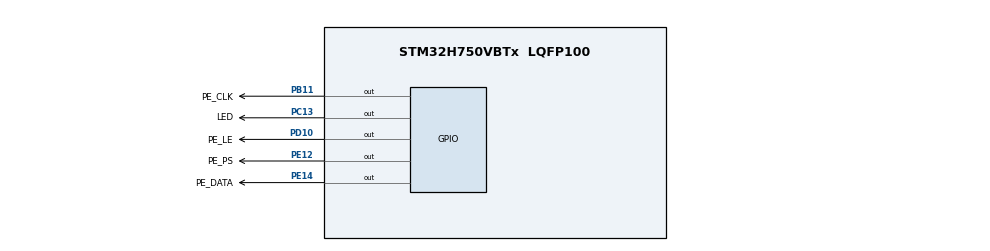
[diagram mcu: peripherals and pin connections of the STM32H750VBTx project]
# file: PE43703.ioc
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CORTEX_M7.CPU_DCache=Disabled
CORTEX_M7.CPU_ICache=Disabled
CORTEX_M7.default_mode_Activation=1
Mcu.Family=STM32H7
Mcu.Name=STM32H750VBTx
Mcu.Package=LQFP100
NVIC.PriorityGroup=NVIC_PRIORITYGROUP_4
PA13\ (JTMS/SWDIO).Mode=Serial_Wire
PA13\ (JTMS/SWDIO).Signal=DEBUG_JTMS-SWDIO
PA14\ (JTCK/SWCLK).Mode=Serial_Wire
PA14\ (JTCK/SWCLK).Signal=DEBUG_JTCK-SWCLK
PB11.GPIO_Label=PE_CLK
PB11.GPIO_Speed=GPIO_SPEED_FREQ_VERY_HIGH
PB11.Signal=GPIO_Output
PC13.GPIO_Label=LED
PC13.Signal=GPIO_Output
PD10.GPIO_Label=PE_LE
PD10.GPIO_Speed=GPIO_SPEED_FREQ_VERY_HIGH
PD10.Signal=GPIO_Output
PE12.GPIO_Label=PE_PS
PE12.GPIO_Speed=GPIO_SPEED_FREQ_VERY_HIGH
PE12.PinState=GPIO_PIN_SET
PE12.Signal=GPIO_Output
PE14.GPIO_Label=PE_DATA
PE14.GPIO_Speed=GPIO_SPEED_FREQ_VERY_HIGH
PE14.Signal=GPIO_Output
PH0-OSC_IN\ (PH0).Mode=HSE-External-Clock-Source
PH0-OSC_IN\ (PH0).Signal=RCC_OSC_IN
ProjectManager.HeapSize=0x200
ProjectManager.StackSize=0x400
ProjectManager.TargetToolchain=MDK-ARM V5.32
RCC.ADCFreq_Value=50390625
RCC.APB1Freq_Value=120000000
RCC.APB2Freq_Value=120000000
RCC.APB3Freq_Value=120000000
RCC.APB4Freq_Value=120000000
RCC.CortexFreq_Value=480000000
RCC.D1PPRE=RCC_APB3_DIV2
RCC.D2PPRE1=RCC_APB1_DIV2
RCC.D2PPRE2=RCC_APB2_DIV2
RCC.D3PPRE=RCC_APB4_DIV2
RCC.DIVM1=5
RCC.DIVN1=192
RCC.HCLKFreq_Value=240000000
RCC.HPRE=RCC_HCLK_DIV2
RCC.PLLFRACN=0
RCC.PLLSourceVirtual=RCC_PLLSOURCE_HSE
RCC.PWR_Regulator_Voltage_Scale=PWR_REGULATOR_VOLTAGE_SCALE0
RCC.ProductRev=revV
RCC.SYSCLKFreq_VALUE=480000000
RCC.SYSCLKSource=RCC_SYSCLKSOURCE_PLLCLK
RCC.USBFreq_Value=480000000
board=custom

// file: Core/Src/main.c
/* USER CODE BEGIN Header */
/**
  ******************************************************************************
  * @file           : main.c
  * @brief          : Main program body
  ******************************************************************************
  * @attention
  *
  * Copyright (c) 2024 STMicroelectronics.
  * All rights reserved.
  *
  * This software is licensed under terms that can be found in the LICENSE file
  * in the root directory of this software component.
  * If no LICENSE file comes with this software, it is provided AS-IS.
  *
  ******************************************************************************
  */
/* USER CODE END Header */
#include "main.h"
#include "gpio.h"

/* USER CODE BEGIN Includes */
#include "pe43703.h"
/* USER CODE END Includes */

void SystemClock_Config(void);
static void MPU_Config(void);

int main(void)
{

  /* MPU Configuration--------------------------------------------------------*/
  MPU_Config();

  /* MCU Configuration--------------------------------------------------------*/

  /* Reset of all peripherals, Initializes the Flash interface and the Systick. */
  HAL_Init();

  /* Configure the system clock */
  SystemClock_Config();

  /* Initialize all configured peripherals */
  MX_GPIO_Init();
  /* USER CODE BEGIN 2 */
   uint8_t db = 0;
  /* USER CODE END 2 */

  /* Infinite loop */
  /* USER CODE BEGIN WHILE */
  while (1)
  {
     PE43703_set_serial(db);
     db++;
     if(db > 127){
       db = 0;
     }
    HAL_Delay(1000);
    HAL_GPIO_TogglePin(LED_GPIO_Port,LED_Pin);
    //delay_n(1);//344ns
    /* USER CODE END WHILE */

  }
}

void SystemClock_Config(void)
{
  RCC_OscInitTypeDef RCC_OscInitStruct = {0};
  RCC_ClkInitTypeDef RCC_ClkInitStruct = {0};

  /** Supply configuration update enable
  */
  HAL_PWREx_ConfigSupply(PWR_LDO_SUPPLY);

  /** Configure the main internal regulator output voltage
  */
  __HAL_PWR_VOLTAGESCALING_CONFIG(PWR_REGULATOR_VOLTAGE_SCALE1);

  while(!__HAL_PWR_GET_FLAG(PWR_FLAG_VOSRDY)) {}

  __HAL_RCC_SYSCFG_CLK_ENABLE();
  __HAL_PWR_VOLTAGESCALING_CONFIG(PWR_REGULATOR_VOLTAGE_SCALE0);

  while(!__HAL_PWR_GET_FLAG(PWR_FLAG_VOSRDY)) {}

  /** Initializes the RCC Oscillators according to the specified parameters
  * in the RCC_OscInitTypeDef structure.
  */
  RCC_OscInitStruct.OscillatorType = RCC_OSCILLATORTYPE_HSE;
  RCC_OscInitStruct.HSEState = RCC_HSE_BYPASS;
  RCC_OscInitStruct.PLL.PLLState = RCC_PLL_ON;
  RCC_OscInitStruct.PLL.PLLSource = RCC_PLLSOURCE_HSE;
  RCC_OscInitStruct.PLL.PLLM = 5;
  RCC_OscInitStruct.PLL.PLLN = 192;
  RCC_OscInitStruct.PLL.PLLP = 2;
  RCC_OscInitStruct.PLL.PLLQ = 2;
  RCC_OscInitStruct.PLL.PLLR = 2;
  RCC_OscInitStruct.PLL.PLLRGE = RCC_PLL1VCIRANGE_2;
  RCC_OscInitStruct.PLL.PLLVCOSEL = RCC_PLL1VCOWIDE;
  RCC_OscInitStruct.PLL.PLLFRACN = 0;
  if (HAL_RCC_OscConfig(&RCC_OscInitStruct) != HAL_OK)
  {
    Error_Handler();
  }

  /** Initializes the CPU, AHB and APB buses clocks
  */
  RCC_ClkInitStruct.ClockType = RCC_CLOCKTYPE_HCLK|RCC_CLOCKTYPE_SYSCLK
                              |RCC_CLOCKTYPE_PCLK1|RCC_CLOCKTYPE_PCLK2
                              |RCC_CLOCKTYPE_D3PCLK1|RCC_CLOCKTYPE_D1PCLK1;
  RCC_ClkInitStruct.SYSCLKSource = RCC_SYSCLKSOURCE_PLLCLK;
  RCC_ClkInitStruct.SYSCLKDivider = RCC_SYSCLK_DIV1;
  RCC_ClkInitStruct.AHBCLKDivider = RCC_HCLK_DIV2;
  RCC_ClkInitStruct.APB3CLKDivider = RCC_APB3_DIV2;
  RCC_ClkInitStruct.APB1CLKDivider = RCC_APB1_DIV2;
  RCC_ClkInitStruct.APB2CLKDivider = RCC_APB2_DIV2;
  RCC_ClkInitStruct.APB4CLKDivider = RCC_APB4_DIV2;

  if (HAL_RCC_ClockConfig(&RCC_ClkInitStruct, FLASH_LATENCY_4) != HAL_OK)
  {
    Error_Handler();
  }
}

 /* MPU Configuration */

void MPU_Config(void)
{
  MPU_Region_InitTypeDef MPU_InitStruct = {0};

  /* Disables the MPU */
  HAL_MPU_Disable();

  /** Initializes and configures the Region and the memory to be protected
  */
  MPU_InitStruct.Enable = MPU_REGION_ENABLE;
  MPU_InitStruct.Number = MPU_REGION_NUMBER0;
  MPU_InitStruct.BaseAddress = 0x0;
  MPU_InitStruct.Size = MPU_REGION_SIZE_4GB;
  MPU_InitStruct.SubRegionDisable = 0x87;
  MPU_InitStruct.TypeExtField = MPU_TEX_LEVEL0;
  MPU_InitStruct.AccessPermission = MPU_REGION_NO_ACCESS;
  MPU_InitStruct.DisableExec = MPU_INSTRUCTION_ACCESS_DISABLE;
  MPU_InitStruct.IsShareable = MPU_ACCESS_SHAREABLE;
  MPU_InitStruct.IsCacheable = MPU_ACCESS_NOT_CACHEABLE;
  MPU_InitStruct.IsBufferable = MPU_ACCESS_NOT_BUFFERABLE;

  HAL_MPU_ConfigRegion(&MPU_InitStruct);
  /* Enables the MPU */
  HAL_MPU_Enable(MPU_PRIVILEGED_DEFAULT);

}

void Error_Handler(void)
{
  __disable_irq();
  while (1)
  {
  }
}
